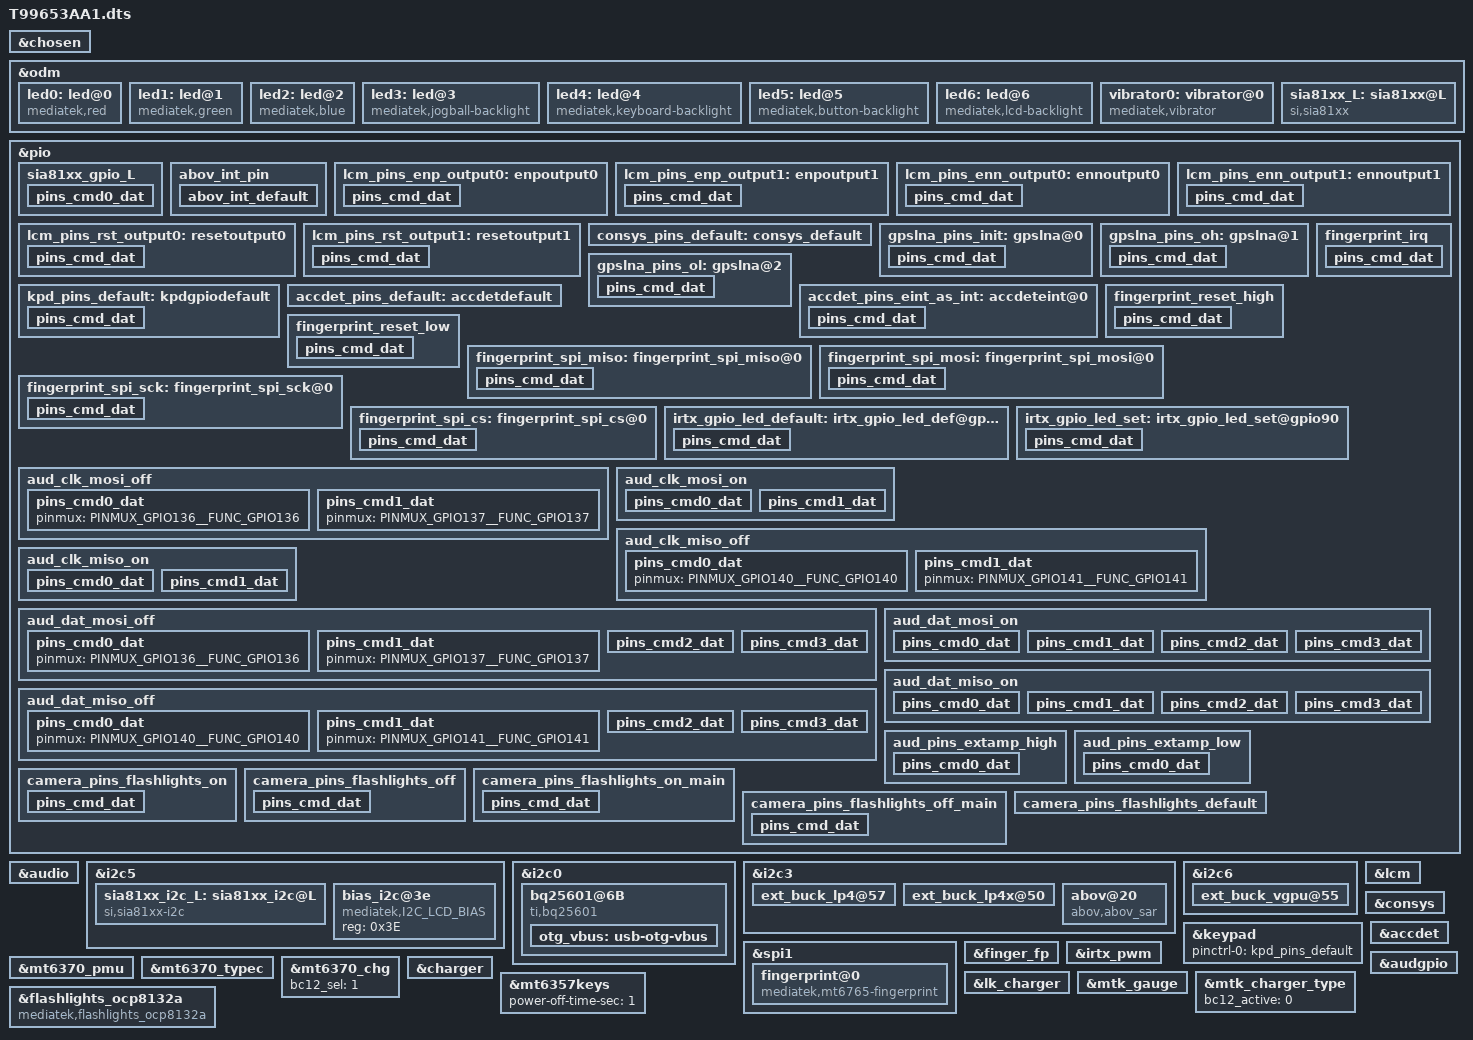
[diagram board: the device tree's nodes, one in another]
// SPDX-License-Identifier: GPL-2.0+
/*
 * Copyright (c) 2019 MediaTek Inc.
 *
 */

#include <dt-bindings/interrupt-controller/arm-gic.h>
#include <dt-bindings/interrupt-controller/irq.h>
#include <dt-bindings/pinctrl/mt6765-pinfunc.h>
#include <dt-bindings/clock/mt6765-clk.h>

/dts-v1/;
/plugin/;

/* chosen */
&chosen {

	/* fpga may has no lk, we need to specify display info here */
	/* fb buffer is reserved using this dts by memory node above */
	atag,videolfb-fb_base_h = <0x0>;
	atag,videolfb-fb_base_l = <0x5e605000>;
	atag,videolfb-islcmfound = <1>;
	/* because no lk, so lcm is not inited */
	atag,videolfb-islcm_inited = <0>;
	atag,videolfb-fps= <6000>;
	atag,videolfb-vramSize= <0x017bb000>;
	atag,videolfb-lcmname= "nt35695B_fhd_dsi_cmd_auo_rt5081_drv";
};

&odm {
	led0:led@0 {
		compatible = "mediatek,red";
		led_mode = <0>;
		data = <1>;
		pwm_config = <0 0 0 0 0>;
	};
	led1:led@1 {
		compatible = "mediatek,green";
		led_mode = <0>;
		data = <1>;
		pwm_config = <0 0 0 0 0>;
	};
	led2:led@2 {
		compatible = "mediatek,blue";
		led_mode = <0>;
		data = <1>;
		pwm_config = <0 0 0 0 0>;
	};
	led3:led@3 {
		compatible = "mediatek,jogball-backlight";
		led_mode = <0>;
		data = <1>;
		pwm_config = <0 0 0 0 0>;
	};
	led4:led@4 {
		compatible = "mediatek,keyboard-backlight";
		led_mode = <0>;
		data = <1>;
		pwm_config = <0 0 0 0 0>;
	};
	led5:led@5 {
		compatible = "mediatek,button-backlight";
		led_mode = <0>;
		data = <1>;
		pwm_config = <0 0 0 0 0>;
	};
	led6:led@6 {
		compatible = "mediatek,lcd-backlight";
		led_mode = <5>;
		data = <1>;
		pwm_config = <0 1 0 0 0>;//bug599756, liuchunyang.wt, modify, 20201113, modify lcd backlight PWM frequency
	};
	vibrator0:vibrator@0 {
		compatible = "mediatek,vibrator";
		vib_timer = <25>;
		vib_limit = <9>;
		vib_vol= <9>;
	};
/*+Bugbug589753 liujin.wt, modify, 20201014, audio bringup for sia81xx */
    sia81xx_L:sia81xx@L {
        compatible = "si,sia81xx";
        si,sia81xx_type = "sia8101";
        si,sia81xx_reset = <&pio 152 0>;
        si,sia81xx_owi = <&pio 152 0>;
        pinctrl-names = "sia81xx_gpio";
        pinctrl-0 = <&sia81xx_gpio_L>;

        si,sia81xx_disable_pin = <0>;

        // the same value share a same task
        // valid value range : 0 ~ 7
        timer_task_hdl = <0>;

        channel_num = <0>;
        /*+Bugbug589755 liujin.wt, modify, 20201229, modify config for sia81xx */
        owi_mode = <1>;
        en_x_filter = <0>;
        /*-Bugbug589755 liujin.wt, modify, 20201229, modify config for sia81xx */
        en_dynamic_updata_vdd = <0>;
        dynamic_updata_vdd_port = <0x2>;

    };
};

&pio {
    sia81xx_gpio_L: sia81xx_gpio_L {
        pins_cmd0_dat {
            pinmux = <PINMUX_GPIO152__FUNC_GPIO152>;
            
            slew-rate = <1>;
            bias-disable;
        };
    };
};

&audio {
    si,sia81xx-max-num = <1>;
    si,sia81xx-aux-devs = <&sia81xx_L>;
    si,sia81xx-aux-devs-prefix = "SpkrLeft";
};


&i2c5 {
    #address-cells = <1>;
    #size-cells = <0>;
    clock-frequency = <400000>;
    mediatek,use-open-drain;

    sia81xx_i2c_L: sia81xx_i2c@L {
        compatible = "si,sia81xx-i2c";
        reg = <0x58>;
        si,sia81xx-dev = <&sia81xx_L>;
    };

};
/*-Bugbug589753 liujin.wt, modify, 20201014, audio bringup for sia81xx */

//+bug 589756, yaocankun, add, 20201010, for charger bringup
&i2c0 {
	bq25601@6B {
		compatible = "ti,bq25601";
		reg = <0x6B>;
		ti,bq2560x,usb-vlim = <4600>;
		ti,bq2560x,usb-ilim = <2000>;
		ti,bq2560x,usb-vreg = <4400>;
		ti,bq2560x,usb-ichg = <2000>;
		ti,bq2560x,precharge-current = <256>;
		ti,bq2560x,termination-current = <60>;
		ti,bq2560x,boost-voltage = <4998>;
		ti,bq2560x,boost-current = <1200>;
		ti,bq2560x,enable_term;
		ti,bq2560x,stat-pin-ctrl = <3>;
		ti,bq2560x,vac-ovp-threshold = <6500>;

		otg_vbus: usb-otg-vbus {
			regulator-compatible = "usb-otg-vbus";
			regulator-name = "usb-otg-vbus";
			regulator-min-microvolt = <5000000>;
			regulator-max-microvolt = <5000000>;
			regulator-min-microamp = <500000>;
			regulator-max-microamp = <1200000>;
		};
	};
};
//-bug 589756, yaocankun, add, 20201010, for charger bringup

//+Bug589755,linliwei.wt,MODIFY,20201014,T99653AA1 sar sensor function bring up
&i2c3 {
	ext_buck_lp4@57 {
		regulator-name ="ext_buck_vdd2";
		regulator-min-microvolt = <300000>;
		regulator-max-microvolt = <1300000>;
		vsel_pin = <0>;
	};

	ext_buck_lp4x@50 {
		regulator-name ="ext_buck_vddq";
		regulator-min-microvolt = <300000>;
		regulator-max-microvolt = <1300000>;
		vsel_pin = <1>;
	};
       abov@20 {
               label = "AbovCapSense";
               compatible = "abov,abov_sar";
               reg = <0x20>;
               //cap_vdd-supply = <&pm8953_l10>;
               //interrupt-parent = <&tlmm>;
               //interrupts = <45 0x2008>;
               //abov,irq-gpio = <&tlmm 45 0x2008>; /* IRQ */
               interrupt-parent = <&pio>;
               interrupts = <4 IRQ_TYPE_EDGE_FALLING 4 0>;
               abov,irq-gpio = <&pio 4 0>;
               pinctrl-names = "abov_int_default";
               pinctrl-0 = <&abov_int_default>;
               cap,use_channel = <0x0f>;
               cap,use_channel_top = <0x01>;
               cap,use_channel_bottom = <0x00>;
               cap,scan_period = <0x02>;
               reg_array_len = <2>;
               reg_array_val = <0x18 0x5a 0x19 0x93>;
       };
};
&pio{
       abov_int_pin {
               abov_int_default: abov_int_default {
               /* active state */
               pinmux = <PINMUX_GPIO4__FUNC_GPIO4>;
               slew-rate = <2>;
               bias-pull-up;
           };
       };
};
//-Bug589755,linliwei.wt,MODIFY,20201014,T99653AA1 sar sensor function bring up

//+bug589756, sheqihao.wt, MODIFY, 20201009, LCD ILI9882H Bringup
&i2c5 {
	bias_i2c@3e {
		compatible = "mediatek,I2C_LCD_BIAS";
		reg = <0x3E>;
		status = "okay";
	};
};
//-bug589756, sheqihao.wt, MODIFY, 20201009, LCD ILI9882H Bringup

&i2c6 {
	ext_buck_vgpu@55 {
		regulator-name ="ext_buck_vgpu";
		regulator-min-microvolt = <300000>;
		regulator-max-microvolt = <1300000>;
		vsel_pin = <2>;
	};
};
//+bug589756, sheqihao.wt, MODIFY, 20201009, LCD ILI9882H Bringup
/*LCM start*/
&lcm {
	pinctrl-names = "state_enp_output0","state_enp_output1", "state_enn_output0",
		"state_enn_output1","state_reset_output0", "state_reset_output1";
	pinctrl-0 = <&lcm_pins_enp_output0>;
	pinctrl-1 = <&lcm_pins_enp_output1>;
	pinctrl-2 = <&lcm_pins_enn_output0>;
	pinctrl-3 = <&lcm_pins_enn_output1>;
	pinctrl-4 = <&lcm_pins_rst_output0>;
	pinctrl-5 = <&lcm_pins_rst_output1>;
	status = "okay";
};
&pio {
	lcm_pins_enp_output0: enpoutput0 {
		pins_cmd_dat {
			pinmux = <PINMUX_GPIO150__FUNC_GPIO150>;
			slew-rate = <1>;
			output-low;
		};
	};
	lcm_pins_enp_output1: enpoutput1 {
		pins_cmd_dat {
			pinmux = <PINMUX_GPIO150__FUNC_GPIO150>;
			slew-rate = <1>;
			output-high;
		};
	};
	lcm_pins_enn_output0: ennoutput0 {
		pins_cmd_dat {
			pinmux = <PINMUX_GPIO151__FUNC_GPIO151>;
			slew-rate = <1>;
			output-low;
		};
	};
	lcm_pins_enn_output1: ennoutput1 {
		pins_cmd_dat {
			pinmux = <PINMUX_GPIO151__FUNC_GPIO151>;
			slew-rate = <1>;
			output-high;
		};
	};
	lcm_pins_rst_output0: resetoutput0 {
		pins_cmd_dat {
			pinmux = <PINMUX_GPIO45__FUNC_GPIO45>;
			slew-rate = <1>;
			output-low;
		};
	};
	lcm_pins_rst_output1: resetoutput1 {
		pins_cmd_dat {
			pinmux = <PINMUX_GPIO45__FUNC_GPIO45>;
			slew-rate = <1>;
			output-high;
		};
	};
};
/*LCM  end*/

//-bug589756, sheqihao.wt, MODIFY, 20201009, LCD ILI9882H Bringup

/* CONSYS GPIO standardization */
&pio {
	consys_pins_default: consys_default {
	};
	gpslna_pins_init: gpslna@0 {
		pins_cmd_dat {
			pinmux = <PINMUX_GPIO91__FUNC_GPIO91>;
			slew-rate = <0>;
			bias-disable;
			output-low;
		};
	};
	gpslna_pins_oh: gpslna@1 {
		pins_cmd_dat {
			pinmux = <PINMUX_GPIO91__FUNC_GPIO91>;
			slew-rate = <1>;
			output-high;
		};
	};
	gpslna_pins_ol: gpslna@2 {
		pins_cmd_dat {
			pinmux = <PINMUX_GPIO91__FUNC_GPIO91>;
			slew-rate = <1>;
			output-low;
		};
	};
};
&consys {
	pinctrl-names = "default", "gps_lna_state_init",
		"gps_lna_state_oh", "gps_lna_state_ol";
	pinctrl-0 = <&consys_pins_default>;
	pinctrl-1 = <&gpslna_pins_init>;
	pinctrl-2 = <&gpslna_pins_oh>;
	pinctrl-3 = <&gpslna_pins_ol>;
	status = "okay";
};
/* CONSYS end */

&keypad {
	pinctrl-names = "default";
	pinctrl-0 = <&kpd_pins_default>;
};

&pio {
	kpd_pins_default: kpdgpiodefault {
		pins_cmd_dat {
			pinmux = <PINMUX_GPIO93__FUNC_KPCOL0>;
			bias-pull-up = <MTK_PUPD_SET_R1R0_10>;
			output-low;
			input-schmitt-enable;
		};
	};
};


/* accdet start */
&accdet {
	accdet-mic-vol = <6>;
	headset-mode-setting = <0x500 0x500 1 0x1f0 0x800 0x800 0x20 0x44>;
	accdet-plugout-debounce = <1>;
	accdet-mic-mode = <1>;
	headset-eint-level-pol = <8>;
	headset-three-key-threshold = <0 80 220 400>;
	headset-three-key-threshold-CDD = <0 121 192 600>;
	headset-four-key-threshold = <0 58 121 192 400>;
	pinctrl-names = "default", "state_eint_as_int";
	pinctrl-0 = <&accdet_pins_default>;
	pinctrl-1 = <&accdet_pins_eint_as_int>;
	status = "okay";
};
&pio {
	accdet_pins_default: accdetdefault {
	};
	accdet_pins_eint_as_int: accdeteint@0 {
		pins_cmd_dat {
			pinmux = <PINMUX_GPIO9__FUNC_GPIO9>;
			slew-rate = <0>;
			bias-disable;
		};
	};
};
/* accdet end */

//+Bug589756 xiaoguang.wt, MODIFY, 20201030, fingerprint bringup
/* FINGERPRINT start */
&spi1{
	#address-cells = <1>;
	#size-cells = <0>;
	fingerprint@0 {
		compatible = "mediatek,mt6765-fingerprint";
		reg = <0>;
		spi-max-frequency = <10000000>;
		netlink-event = <30>;
		status = "okay";
	};
};

&finger_fp{
	reg = <0>;
	interrupt-parent = <&pio>;
    interrupts = <5 IRQ_TYPE_EDGE_RISING 1 0>;
	vdd_ldo_enable = <0>;
	vio_ldo_enable = <0>;
	config_spi_pin = <1>;

	int-gpio = <&pio 5 0>;
	rst-gpio = <&pio 175 0>;
	debounce = <12 0>;

	pinctrl-names ="fingerprint_reset_high",
		"fingerprint_reset_low",
		"fingerprint_spi_miso",
		"fingerprint_spi_mosi",
		"fingerprint_spi_sck",
		"fingerprint_spi_cs",
		"fingerprint_irq";
	pinctrl-0 = <&fingerprint_reset_high>;
	pinctrl-1 = <&fingerprint_reset_low>;
	pinctrl-2 = <&fingerprint_spi_miso>;
	pinctrl-3 = <&fingerprint_spi_mosi>;
	pinctrl-4 = <&fingerprint_spi_sck>;
	pinctrl-5 = <&fingerprint_spi_cs>;
	pinctrl-6 = <&fingerprint_irq>;
	status = "okay";
};

&pio {
	fingerprint_reset_high: fingerprint_reset_high {
		pins_cmd_dat {
			pinmux = <PINMUX_GPIO175__FUNC_GPIO175>; 
			slew-rate = <1>;
			bias-disable;
			output-high;
		};
	};
	fingerprint_reset_low: fingerprint_reset_low {
		pins_cmd_dat {
			pinmux = <PINMUX_GPIO175__FUNC_GPIO175>;
			slew-rate = <1>;
			bias-disable;
			output-low;
		};
	};
	
	fingerprint_spi_miso:fingerprint_spi_miso@0{
		pins_cmd_dat {
			pinmux = <PINMUX_GPIO25__FUNC_SPI1_A_MI>; 
			slew-rate = <0>;
			bias-pull-up = <11>;
			//output-low;
		};
	};
	fingerprint_spi_mosi:fingerprint_spi_mosi@0{
		pins_cmd_dat {
			pinmux = <PINMUX_GPIO27__FUNC_SPI1_A_MO>;  
			slew-rate = <1>;
			bias-pull-up = <11>;
			output-low;
		};
	};
	fingerprint_spi_sck:fingerprint_spi_sck@0{
		pins_cmd_dat {
			pinmux = <PINMUX_GPIO28__FUNC_SPI1_A_CLK>;   
			slew-rate = <1>;
			bias-pull-up = <11>;
			output-low;
		};
	};
	fingerprint_spi_cs:fingerprint_spi_cs@0{
		pins_cmd_dat {
			pinmux = <PINMUX_GPIO26__FUNC_SPI1_A_CSB>; 
			slew-rate = <1>;
			bias-pull-up = <11>;
			output-low;
		};
	};
	
	fingerprint_irq:fingerprint_irq{
		pins_cmd_dat {
			pinmux = <PINMUX_GPIO5__FUNC_GPIO5>; 
			slew-rate = <0>;
			bias-pull-down = <00>;
			//output-low;
		};
	};
};
/* FINGERPRINT end */
//-Bug584789 xiaoguang.wt, MODIFY, 20201030, fingerprint bringup

/* IRTX GPIO end */
&irtx_pwm {
	pinctrl-names = "irtx_gpio_led_default", "irtx_gpio_led_set";
	pinctrl-0 = <&irtx_gpio_led_default>;
	pinctrl-1 = <&irtx_gpio_led_set>;
	status = "okay";
};
&pio {
	irtx_gpio_led_default:irtx_gpio_led_def@gpio90 {
		pins_cmd_dat {
			pinmux = <PINMUX_GPIO90__FUNC_GPIO90>;
			slew-rate = <1>;
			bias-disable;
			output-low;
			input-schmitt-enable = <0>;
		};
	};

	irtx_gpio_led_set:irtx_gpio_led_set@gpio90 {
		pins_cmd_dat {
			pinmux = <PINMUX_GPIO90__FUNC_PWM0>;
			slew-rate = <1>;
			output-high;
		};
	};
};
/* IRTX GPIO Settings -End */

/* AUDIO GPIO standardization */
&audgpio {
/*+Bug541039 liujun5.wt add 20200320 for audio bringup pa pinctrl set*/
	extamp-gpio = <&pio 152 0x0>;
	pinctrl-names = "aud_clk_mosi_off",
			"aud_clk_mosi_on",
			"aud_clk_miso_off",
			"aud_clk_miso_on",
			"aud_dat_mosi_off",
			"aud_dat_mosi_on",
			"aud_dat_miso_off",
			"aud_dat_miso_on",
			"extamp-pullhigh",
			"extamp-pulllow";
	pinctrl-0 = <&aud_clk_mosi_off>;
	pinctrl-1 = <&aud_clk_mosi_on>;
	pinctrl-2 = <&aud_clk_miso_off>;
	pinctrl-3 = <&aud_clk_miso_on>;
	pinctrl-4 = <&aud_dat_mosi_off>;
	pinctrl-5 = <&aud_dat_mosi_on>;
	pinctrl-6 = <&aud_dat_miso_off>;
	pinctrl-7 = <&aud_dat_miso_on>;
	pinctrl-8 = <&aud_pins_extamp_high>;
	pinctrl-9 = <&aud_pins_extamp_low>;
	status = "okay";
};
/*-Bug541039 liujun5.wt add 20200320 for audio bringup pa pinctrl set*/

&pio {
	aud_clk_mosi_off: aud_clk_mosi_off {
		pins_cmd0_dat {
			pinmux = <PINMUX_GPIO136__FUNC_GPIO136>;
		};
		/*+bug598911, liujin.wt, add, 20201102, for audio record pop */
		pins_cmd1_dat {
			pinmux = <PINMUX_GPIO137__FUNC_GPIO137>;
		};
		/*-bug598911, liujin.wt, add, 20201102, for audio record pop */
	};

	aud_clk_mosi_on: aud_clk_mosi_on {
		pins_cmd0_dat {
			pinmux = <PINMUX_GPIO136__FUNC_AUD_CLK_MOSI>;
		/*+bug598911, liujin.wt, add, 20201102, for audio record pop */
			input-schmitt-enable;
		};
		pins_cmd1_dat {
			pinmux = <PINMUX_GPIO137__FUNC_AUD_SYNC_MOSI>;
			input-schmitt-enable;
		/*-bug598911, liujin.wt, add, 20201102, for audio record pop */
		};
	};

	aud_clk_miso_off: aud_clk_miso_off {
		pins_cmd0_dat {
			pinmux = <PINMUX_GPIO140__FUNC_GPIO140>;
		};
		/*+bug598911, liujin.wt, add, 20201102, for audio record pop */
		pins_cmd1_dat {
			pinmux = <PINMUX_GPIO141__FUNC_GPIO141>;
		};
		/*-bug598911, liujin.wt, add, 20201102, for audio record pop */
	};

	aud_clk_miso_on: aud_clk_miso_on {
		pins_cmd0_dat {
			pinmux = <PINMUX_GPIO140__FUNC_AUD_CLK_MISO>;
		/*+bug598911, liujin.wt, add, 20201102, for audio record pop */
			input-schmitt-enable;
		};
		pins_cmd1_dat {
			pinmux = <PINMUX_GPIO141__FUNC_AUD_SYNC_MISO>;
			input-schmitt-enable;
		/*-bug598911, liujin.wt, add, 20201102, for audio record pop */
		};
	};

	aud_dat_mosi_off: aud_dat_mosi_off {
		/*+bug598911, liujin.wt, add, 20201102, for audio record pop */
		pins_cmd0_dat {
			pinmux = <PINMUX_GPIO136__FUNC_GPIO136>;
		};
		pins_cmd1_dat {
			pinmux = <PINMUX_GPIO137__FUNC_GPIO137>;
		};	
		/*-bug598911, liujin.wt, add, 20201102, for audio record pop */
		pins_cmd2_dat {
			pinmux = <PINMUX_GPIO138__FUNC_GPIO138>;
			input-enable;
			slew-rate = <0>;
			bias-disable;
		};
		pins_cmd3_dat {
			pinmux = <PINMUX_GPIO139__FUNC_GPIO139>;
			input-enable;
			slew-rate = <0>;
			bias-disable;
		};
	};

	aud_dat_mosi_on: aud_dat_mosi_on {
		/*+bug598911, liujin.wt, add, 20201102, for audio record pop */
		pins_cmd0_dat {
			pinmux = <PINMUX_GPIO136__FUNC_AUD_CLK_MOSI>;
			input-schmitt-enable;
		};
		pins_cmd1_dat {
			pinmux = <PINMUX_GPIO137__FUNC_AUD_SYNC_MOSI>;
			input-schmitt-enable;
		};
		pins_cmd2_dat {
			pinmux = <PINMUX_GPIO138__FUNC_AUD_DAT_MOSI0>;
			input-schmitt-enable;
		};
		pins_cmd3_dat {
			pinmux = <PINMUX_GPIO139__FUNC_AUD_DAT_MOSI1>;
			input-schmitt-enable;
		};
		/*-bug598911, liujin.wt, add, 20201102, for audio record pop */
	};

	aud_dat_miso_off: aud_dat_miso_off {
		/*+bug598911, liujin.wt, add, 20201102, for audio record pop */
		pins_cmd0_dat {
			pinmux = <PINMUX_GPIO140__FUNC_GPIO140>;
		};
		pins_cmd1_dat {
			pinmux = <PINMUX_GPIO141__FUNC_GPIO141>;
		};
		/*-bug598911, liujin.wt, add, 20201102, for audio record pop */
		pins_cmd2_dat {
			pinmux = <PINMUX_GPIO142__FUNC_GPIO142>;
			input-enable;
			slew-rate = <0>;
			bias-disable;
		};
		pins_cmd3_dat {
			pinmux = <PINMUX_GPIO143__FUNC_GPIO143>;
			input-enable;
			slew-rate = <0>;
			bias-disable;
		};
	};

	aud_dat_miso_on: aud_dat_miso_on {
		/*+bug598911, liujin.wt, add, 20201102, for audio record pop */
		pins_cmd0_dat {
			pinmux = <PINMUX_GPIO140__FUNC_AUD_CLK_MISO>;
			input-schmitt-enable;
		};
		pins_cmd1_dat {
			pinmux = <PINMUX_GPIO141__FUNC_AUD_SYNC_MISO>;
			input-schmitt-enable;
		};
		pins_cmd2_dat {
			pinmux = <PINMUX_GPIO142__FUNC_AUD_DAT_MISO0>;
			input-schmitt-enable;
		};
		pins_cmd3_dat {
			pinmux = <PINMUX_GPIO143__FUNC_AUD_DAT_MISO1>;
			input-schmitt-enable;
		};
		/*-bug598911, liujin.wt, add, 20201102, for audio record pop */
	};

	/* +Bug541039 liujun5.wt add 20200320 for audio bringup pa pinctrl set*/
	aud_pins_extamp_high: aud_pins_extamp_high {
		pins_cmd0_dat {
			pinmux = <PINMUX_GPIO152__FUNC_GPIO152>;
			slew-rate = <1>;
			output-high;
		};
	};

	aud_pins_extamp_low: aud_pins_extamp_low {
		pins_cmd0_dat {
			pinmux = <PINMUX_GPIO152__FUNC_GPIO152>;
			slew-rate = <1>;
			output-low;
	      };
	};
	/* -Bug541039 liujun5.wt add 20200320 for audio bringup pa pinctrl set*/
};
/* AUDIO end */

&mt6370_pmu {
	mt6370,intr_gpio_num = <11>; /* direct defined GPIO num */
	mt6370,intr_gpio = <&pio 11 0x0>;
};

&mt6370_typec {
	mt6370pd,intr_gpio_num = <41>; /* direct defined GPIO num */
	mt6370pd,intr_gpio = <&pio 41 0x0>;
};

&mt6370_chg {
	bc12_sel = <1>;
};
//+bug 589756, yaocankun, add, 20201010, for charger bringup
&lk_charger {
	power_path_support;
	ac_charger_input_current = <2000000>;
	non_std_ac_charger_current = <500000>;
	charging_host_charger_current = <1500000>;
	ta_ac_charger_current = <2000000>;
};

&charger {
	charger = <&mtk_charger_type>;
/* common */
	battery_cv = <4400000>;
	max_charger_voltage = <6500000>;
	min_charger_voltage = <4600000>;

	/* sw jeita */
	enable_sw_jeita;
	jeita_temp_above_t4_cv = <4100000>;
	jeita_temp_t3_to_t4_cv = <4100000>;
	jeita_temp_t2_to_t3_cv = <4400000>;
	jeita_temp_t1_to_t2_cv = <4400000>;
	jeita_temp_t0_to_t1_cv = <4400000>;
	jeita_temp_below_t0_cv = <4400000>;
	jeita_temp_above_t4_cc = <0>;
//+chk 69775, liyiying.wt, modify, 2020/12/03,  jeita for limit
	jeita_temp_t3_to_t4_cc = <1500000>;
	jeita_temp_t2_to_t3_cc = <2040000>;
	jeita_temp_t1_to_t2_cc = <900000>;
//-chk 69775, liyiying.wt, modify, 2020/12/03, jeita for limit
	jeita_temp_t0_to_t1_cc = <0>;
	jeita_temp_below_t0_cc = <0>;
//+chk 69775, liyiying.wt, modify, 2020/12/03,  jeita for limit
	temp_t4_thres = <55>;
	temp_t4_thres_minus_x_degree = <53>;
	temp_t3_thres = <45>;
	temp_t3_thres_minus_x_degree = <44>;
	temp_t2_thres = <15>;
	temp_t2_thres_plus_x_degree = <17>;
	temp_t1_thres = <0>;
	temp_t1_thres_plus_x_degree = <2>;
	temp_t0_thres = <0>;
	temp_t0_thres_plus_x_degree = <0>;
	temp_neg_10_thres = <0>;
//-chk 69775, liyiying.wt, modify, 2020/12/03,  jeita for limit

//+chk 69775, liyiying.wt, modify, 2020/12/03,  jeita for limit
	/* battery temperature protection */
	enable_min_charge_temp;
	min_charge_temp = <0>;
	min_charge_temp_plus_x_degree = <2>;
	max_charge_temp = <55>;
	max_charge_temp_minus_x_degree = <53>;
//-chk 69775, liyiying.wt, modify, 2020/12/03,  jeita for limit

	/* charging current */
	usb_charger_current = <500000>;
//+bug 584789, liyiying.wt, modify, 2020/12/24, optimize charging speed
	ac_charger_current = <2040000>;
//-bug 584789, liyiying.wt, modify, 2020/12/24, optimize charging speed
//+chk 69775, liyiying.wt, modify, 2020/12/03,  jeita for limit
	ac_charger_input_current = <2200000>;
//-chk 69775, liyiying.wt, modify, 2020/12/03,  jeita for limit
	charging_host_charger_current = <1500000>;

};
#include <dt-bindings/iio/mt635x-auxadc.h>

&mtk_gauge {
	charger = <&mtk_charger_type>;
	/* update bat voltage adc */
	io-channels = <&pmic_auxadc AUXADC_BAT_TEMP>,
			<&pmic_auxadc AUXADC_ISENSE>,
			<&pmic_auxadc AUXADC_VBIF>,
			<&pmic_auxadc AUXADC_IMP>,
			<&auxadc 2>;
	io-channel-names = "pmic_battery_temp",
			"pmic_battery_voltage",
			"pmic_bif_voltage",
			"pmic_ptim_voltage",
			"batteryID-channel";
	/* battery prop */
//+bug 589756, yaocankun, mod, 20201105, merge bat0 curve
	g_temperature = <(50) (25) (10) (0) (-10) (-25) (-30) (-35) (-40) (-45)>;
	g_FG_PSEUDO100 = <98 100 100 100
		98 100 100 100
		98 100 100 100
		98 100 100 100
		98 100 100 100
		100 100 100 100
		100 100 100 100
		100 100 100 100
		100 100 100 100
		100 100 100 100>;
	g_Q_MAX = <5041 2712 2490 1965
		5064 2851 2468 1984
		5024 2432 2310 1946
		4609 1991 1858 1873
		3507 1960 1843 1851
		2211 1652 1533 1541
		2201 1642 1523 1531
		2191 1632 1513 1521
		2181 1622 1503 1511
		2171 1612 1493 1501>;
	g_Q_MAX_H_CURRENT = <5041 2412 2190 1665
		5064 2551 2168 1684
		5024 2132 2010 1646
		4609 1691 1558 1573
		3507 1660 1543 1551
		2210 1650 1533 1541
		2200 1640 1523 1531
		2190 1630 1513 1521
		2180 1620 1503 1511
		2170 1610 1493 1501>;
	ACTIVE_TABLE = <(5)>;
//-bug 589756, yaocankun, mod, 20201105, merge bat0 curve


};
&mtk_charger_type {
	bc12_active = <0>;  //Chk 4535,lizerong,modify,20201016,logic ic bringup
};
//-bug 589756, yaocankun, add, 20201010, for charger bringup
//+extr rnn-1192, yaocankun, add, 20201022, 11s long power key press shutdown
&mt6357keys {
		power-off-time-sec = <1>;/* timeout period 0:8sec; 1:11sec;  2:14sec; 3:5sec */
};
//-extr rnn-1192, yaocankun, add, 20201022, 11s long power key press shutdown

//+bug584789 chenbocheng.wt, add, 2020/10/15, flashlight ocp8132a bring up
&pio {
	camera_pins_flashlights_on: camera_pins_flashlights_on {
		pins_cmd_dat {
			pinmux = <PINMUX_GPIO159__FUNC_GPIO159>;
			slew-rate = <1>;
			output-high;
		};
	};
	camera_pins_flashlights_off: camera_pins_flashlights_off {
		pins_cmd_dat {
			pinmux = <PINMUX_GPIO159__FUNC_GPIO159>;
			slew-rate = <1>;
			output-low;
		};
	};
	camera_pins_flashlights_on_main: camera_pins_flashlights_on_main {
		pins_cmd_dat {
			pinmux = <PINMUX_GPIO153__FUNC_GPIO153>;
			slew-rate = <1>;
			output-high;
		};
	};
	camera_pins_flashlights_off_main: camera_pins_flashlights_off_main {
		pins_cmd_dat {
			pinmux = <PINMUX_GPIO153__FUNC_GPIO153>;
			slew-rate = <1>;
			output-low;
		};
	};
	camera_pins_flashlights_default: camera_pins_flashlights_default {
	};

};
&flashlights_ocp8132a {
		compatible = "mediatek,flashlights_ocp8132a";
		pinctrl-names = "default",
			"flashlights_on",
			"flashlights_off",
			"flashlights_on_main",
			"flashlights_off_main";

		pinctrl-0 = <&camera_pins_flashlights_default>;
		pinctrl-1 = <&camera_pins_flashlights_on>;
		pinctrl-2 = <&camera_pins_flashlights_off>;
		pinctrl-3 = <&camera_pins_flashlights_on_main>;
		pinctrl-4 = <&camera_pins_flashlights_off_main>;
};
//-bug584789 chenbocheng.wt, add, 2020/10/15, flashlight ocp8132a bring up

#include "T99653AA1/cust.dtsi"
//bug584789,chenbocheng.wt,MODIFY,2020/10/13,main s5kgm1 and depth gc02m1b sensor bringup
#include "mediatek/cust_mt6765_camera_t99653.dtsi"
#include "mediatek/cust_mt6765_touch_720x1600.dtsi" //bug589756, sheqihao.wt, MODIFY, 20201009, TP ILI9882H Bringup
/*End of this file, DO NOT ADD ANYTHING HERE*/
